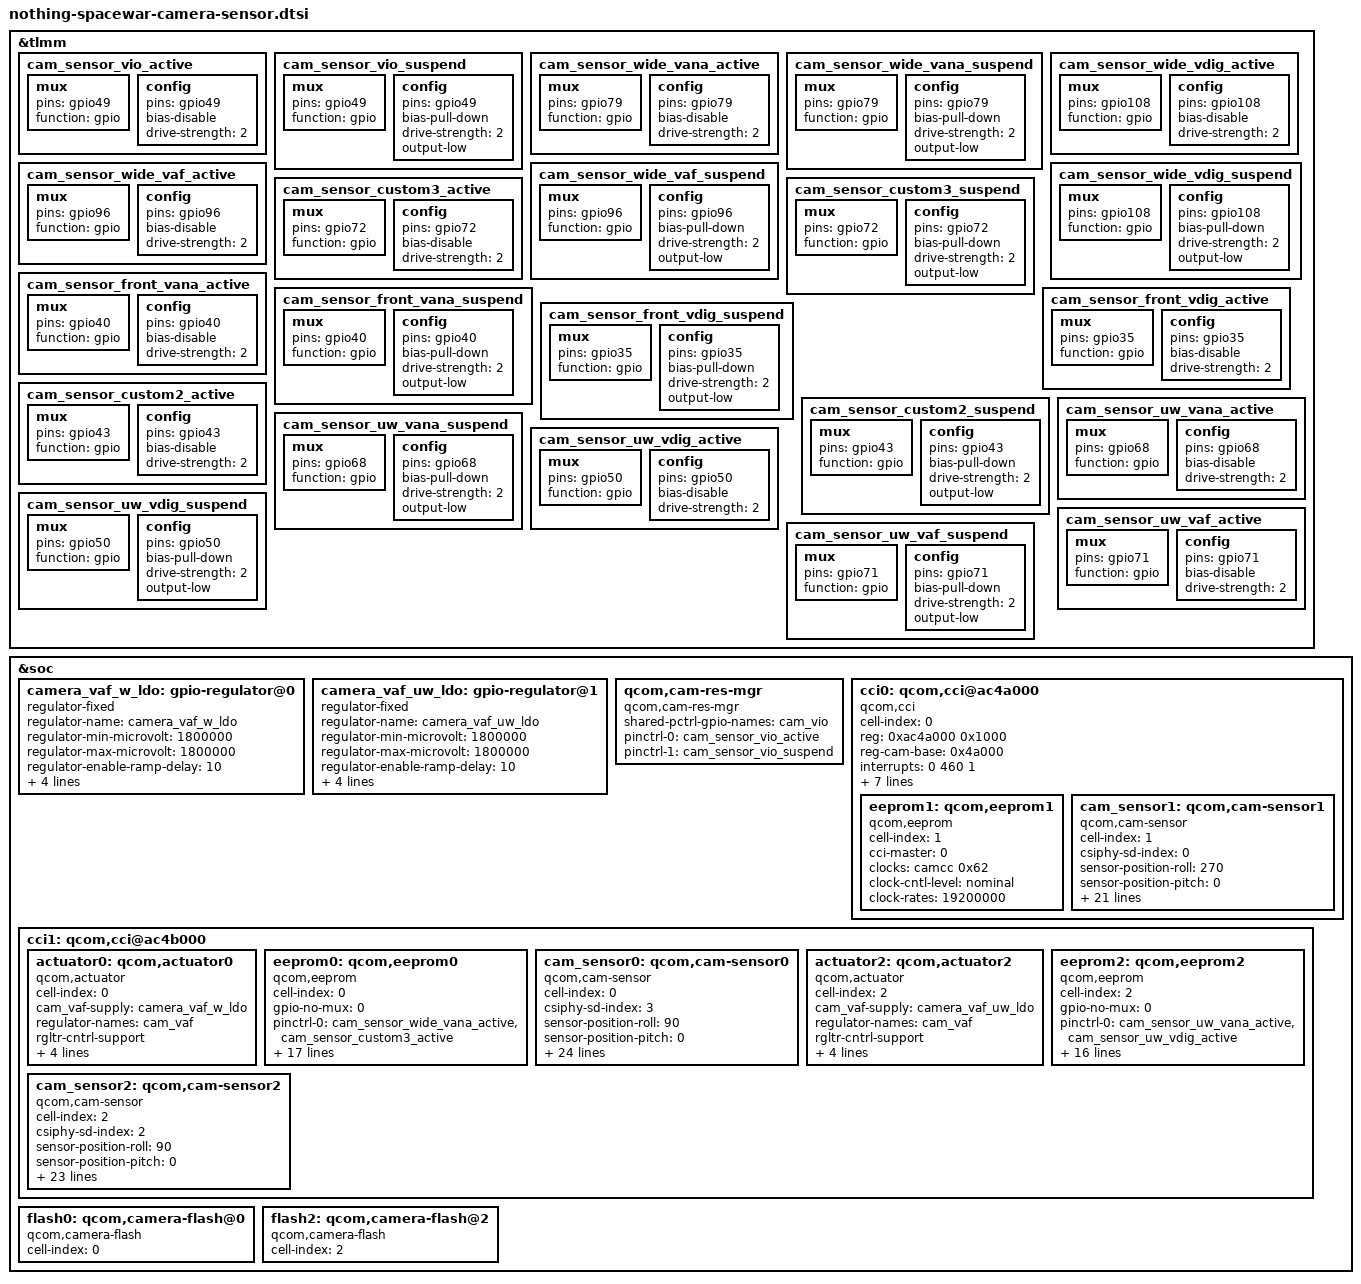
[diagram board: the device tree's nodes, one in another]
// Camera devicetree for Nothing Phone (1) "spacewar"

&tlmm {
	cam_sensor_vio_active: cam_sensor_vio_active {
		mux { pins = "gpio49"; function = "gpio"; };
		config { pins = "gpio49"; bias-disable; drive-strength = <2>; };
	};
	cam_sensor_vio_suspend: cam_sensor_vio_suspend {
		mux { pins = "gpio49"; function = "gpio"; };
		config { pins = "gpio49"; bias-pull-down; drive-strength = <2>; output-low; };
	};

	/* Wide (cam-sensor0) */
	cam_sensor_wide_vana_active: cam_sensor_wide_vana_active {
		mux { pins = "gpio79"; function = "gpio"; };
		config { pins = "gpio79"; bias-disable; drive-strength = <2>; };
	};
	cam_sensor_wide_vana_suspend: cam_sensor_wide_vana_suspend {
		mux { pins = "gpio79"; function = "gpio"; };
		config { pins = "gpio79"; bias-pull-down; drive-strength = <2>; output-low; };
	};
	cam_sensor_wide_vdig_active: cam_sensor_wide_vdig_active {
		mux { pins = "gpio108"; function = "gpio"; };
		config { pins = "gpio108"; bias-disable; drive-strength = <2>; };
	};
	cam_sensor_wide_vdig_suspend: cam_sensor_wide_vdig_suspend {
		mux { pins = "gpio108"; function = "gpio"; };
		config { pins = "gpio108"; bias-pull-down; drive-strength = <2>; output-low; };
	};
	cam_sensor_wide_vaf_active: cam_sensor_wide_vaf_active {
		mux { pins = "gpio96"; function = "gpio"; };
		config { pins = "gpio96"; bias-disable; drive-strength = <2>; };
	};
	cam_sensor_wide_vaf_suspend: cam_sensor_wide_vaf_suspend {
		mux { pins = "gpio96"; function = "gpio"; };
		config { pins = "gpio96"; bias-pull-down; drive-strength = <2>; output-low; };
	};
	cam_sensor_custom3_active: cam_sensor_custom3_active {
		mux { pins = "gpio72"; function = "gpio"; };
		config { pins = "gpio72"; bias-disable; drive-strength = <2>; };
	};
	cam_sensor_custom3_suspend: cam_sensor_custom3_suspend {
		mux { pins = "gpio72"; function = "gpio"; };
		config { pins = "gpio72"; bias-pull-down; drive-strength = <2>; output-low; };
	};

	/* Front (cam-sensor1) */
	cam_sensor_front_vana_active: cam_sensor_front_vana_active {
		mux { pins = "gpio40"; function = "gpio"; };
		config { pins = "gpio40"; bias-disable; drive-strength = <2>; };
	};
	cam_sensor_front_vana_suspend: cam_sensor_front_vana_suspend {
		mux { pins = "gpio40"; function = "gpio"; };
		config { pins = "gpio40"; bias-pull-down; drive-strength = <2>; output-low; };
	};
	cam_sensor_front_vdig_active: cam_sensor_front_vdig_active {
		mux { pins = "gpio35"; function = "gpio"; };
		config { pins = "gpio35"; bias-disable; drive-strength = <2>; };
	};
	cam_sensor_front_vdig_suspend: cam_sensor_front_vdig_suspend {
		mux { pins = "gpio35"; function = "gpio"; };
		config { pins = "gpio35"; bias-pull-down; drive-strength = <2>; output-low; };
	};
	cam_sensor_custom2_active: cam_sensor_custom2_active {
		mux { pins = "gpio43"; function = "gpio"; };
		config { pins = "gpio43"; bias-disable; drive-strength = <2>; };
	};
	cam_sensor_custom2_suspend: cam_sensor_custom2_suspend {
		mux { pins = "gpio43"; function = "gpio"; };
		config { pins = "gpio43"; bias-pull-down; drive-strength = <2>; output-low; };
	};

	/* Ultrawide (cam-sensor2) */
	cam_sensor_uw_vana_active: cam_sensor_uw_vana_active {
		mux { pins = "gpio68"; function = "gpio"; };
		config { pins = "gpio68"; bias-disable; drive-strength = <2>; };
	};
	cam_sensor_uw_vana_suspend: cam_sensor_uw_vana_suspend {
		mux { pins = "gpio68"; function = "gpio"; };
		config { pins = "gpio68"; bias-pull-down; drive-strength = <2>; output-low; };
	};
	cam_sensor_uw_vdig_active: cam_sensor_uw_vdig_active {
		mux { pins = "gpio50"; function = "gpio"; };
		config { pins = "gpio50"; bias-disable; drive-strength = <2>; };
	};
	cam_sensor_uw_vdig_suspend: cam_sensor_uw_vdig_suspend {
		mux { pins = "gpio50"; function = "gpio"; };
		config { pins = "gpio50"; bias-pull-down; drive-strength = <2>; output-low; };
	};
	cam_sensor_uw_vaf_active: cam_sensor_uw_vaf_active {
		mux { pins = "gpio71"; function = "gpio"; };
		config { pins = "gpio71"; bias-disable; drive-strength = <2>; };
	};
	cam_sensor_uw_vaf_suspend: cam_sensor_uw_vaf_suspend {
		mux { pins = "gpio71"; function = "gpio"; };
		config { pins = "gpio71"; bias-pull-down; drive-strength = <2>; output-low; };
	};
};

&soc {
	/* AF VCM LDOs - fixed 1.8V, gpio-enabled */
	camera_vaf_w_ldo: gpio-regulator@0 {
		compatible = "regulator-fixed";
		regulator-name = "camera_vaf_w_ldo";
		regulator-min-microvolt = <1800000>;
		regulator-max-microvolt = <1800000>;
		regulator-enable-ramp-delay = <10>;
		enable-active-high;
		pinctrl-names = "cam_af0_active", "cam_af0_suspend";
		pinctrl-0 = <&cam_sensor_wide_vaf_active>;
		pinctrl-1 = <&cam_sensor_wide_vaf_suspend>;
		gpio = <&tlmm 96 0>;
	};

	camera_vaf_uw_ldo: gpio-regulator@1 {
		compatible = "regulator-fixed";
		regulator-name = "camera_vaf_uw_ldo";
		regulator-min-microvolt = <1800000>;
		regulator-max-microvolt = <1800000>;
		regulator-enable-ramp-delay = <10>;
		enable-active-high;
		pinctrl-names = "cam_af1_active", "cam_af1_suspend";
		pinctrl-0 = <&cam_sensor_uw_vaf_active>;
		pinctrl-1 = <&cam_sensor_uw_vaf_suspend>;
		gpio = <&tlmm 71 0>;
	};

	qcom,cam-res-mgr {
		compatible = "qcom,cam-res-mgr";
		shared-pctrl-gpio-names = "cam_vio";
		pinctrl-names = "cam_vio_active", "cam_vio_suspend";
		pinctrl-0 = <&cam_sensor_vio_active>;
		pinctrl-1 = <&cam_sensor_vio_suspend>;
		status = "ok";
	};

	cci0: qcom,cci@ac4a000 {
		cell-index = <0>;
		compatible = "qcom,cci", "simple-bus";
		reg = <0xac4a000 0x1000>;
		reg-names = "cci";
		reg-cam-base = <0x4a000>;
		interrupt-names = "cci";
		interrupts = <0 460 1>;
		status = "ok";
		gpios = <&tlmm 69 0>, <&tlmm 70 0>;
		gpio-req-tbl-num = <0 1>;
		gpio-req-tbl-flags = <1 1>;
		gpio-req-tbl-label = "CCI_I2C_DATA0", "CCI_I2C_CLK0";
		clock-cntl-level = "lowsvs";
		clock-rates = <37500000 0>;
		#address-cells = <1>;
		#size-cells = <0>;

		/* ===== Front sensor (cci-master 0) ===== */
		eeprom1: qcom,eeprom1 {
			cell-index = <1>;
			compatible = "qcom,eeprom";
			cci-master = <0>;
			status = "ok";
			clocks = <&camcc 0x62>;
			clock-names = "cam_clk";
			clock-cntl-level = "nominal";
			clock-rates = <19200000>;
		};

		cam_sensor1: qcom,cam-sensor1 {
			cell-index = <1>;
			compatible = "qcom,cam-sensor";
			csiphy-sd-index = <0>;
			sensor-position-roll = <270>;
			sensor-position-pitch = <0>;
			sensor-position-yaw = <0>;
			eeprom-src = <&eeprom1>;
			gpio-no-mux = <0>;
			pinctrl-names = "cam_default", "cam_suspend";
			pinctrl-0 = <&cam_sensor_front_vdig_active &cam_sensor_custom2_active>;
			pinctrl-1 = <&cam_sensor_front_vdig_suspend &cam_sensor_custom2_suspend>;
			gpios = <&tlmm 64 0>, <&tlmm 20 0>, <&tlmm 35 0>,
				<&tlmm 49 0>, <&tlmm 43 0>;
			gpio-reset = <1>;
			gpio-vdig = <2>;
			gpio-vio = <3>;
			gpio-custom2 = <4>;
			gpio-req-tbl-num = <0 1 2 3 4>;
			gpio-req-tbl-flags = <1 0 0 0 0>;
			gpio-req-tbl-label = "CAMIF_MCLK1", "CAM_RESET1", "CAM_VDIG1", "CAM_VIO1", "CAM_CUSTOM1";
			cci-master = <0>;
			status = "ok";
			clocks = <&camcc 0x5c>;
			clock-names = "cam_clk";
			clock-cntl-level = "nominal";
			clock-rates = <19200000>;
		};
	};

	cci1: qcom,cci@ac4b000 {
		/* Wide + ultrawide, cci-master 1/0 on the second CCI logical bus */
		#address-cells = <1>;
		#size-cells = <0>;

		/* ===== Wide sensor (cci-master 1) ===== */
		actuator0: qcom,actuator0 {
			cell-index = <0>;
			compatible = "qcom,actuator";
			cam_vaf-supply = <&camera_vaf_w_ldo>;
			regulator-names = "cam_vaf";
			rgltr-cntrl-support;
			rgltr-min-voltage = <1800000>;
			rgltr-max-voltage = <1800000>;
			rgltr-load-current = <1800000>;
			cci-master = <1>;
		};

		eeprom0: qcom,eeprom0 {
			cell-index = <0>;
			compatible = "qcom,eeprom";
			gpio-no-mux = <0>;
			pinctrl-names = "cam_default", "cam_suspend";
			pinctrl-0 = <&cam_sensor_wide_vana_active &cam_sensor_custom3_active>;
			pinctrl-1 = <&cam_sensor_wide_vana_suspend &cam_sensor_custom3_suspend>;
			gpios = <&tlmm 67 0>, <&tlmm 78 0>, <&tlmm 79 0>,
				<&tlmm 72 0>, <&tlmm 108 0>, <&tlmm 49 0>;
			gpio-reset = <1>;
			gpio-vana = <2>;
			gpio-custom1 = <3>;
			gpio-vdig = <4>;
			gpio-vio = <5>;
			gpio-req-tbl-num = <0 1 2 3 4 5>;
			gpio-req-tbl-flags = <1 0 0 0 0 0>;
			gpio-req-tbl-label = "CAMIF_MCLK0", "CAM_RESET0", "CAM_VANA0", "CAM_CUSTOM0", "CAM_VDIG0", "CAM_VIO0";
			cci-master = <1>;
			status = "ok";
			clocks = <&camcc 0x62>;
			clock-names = "cam_clk";
			clock-cntl-level = "nominal";
			clock-rates = <19200000>;
		};

		cam_sensor0: qcom,cam-sensor0 {
			cell-index = <0>;
			compatible = "qcom,cam-sensor";
			csiphy-sd-index = <3>;
			sensor-position-roll = <90>;
			sensor-position-pitch = <0>;
			sensor-position-yaw = <180>;
			actuator-src = <&actuator0>;
			eeprom-src = <&eeprom0>;
			led-flash-src = <&flash0>;
			gpio-no-mux = <0>;
			pinctrl-names = "cam_default", "cam_suspend";
			pinctrl-0 = <&cam_sensor_wide_vana_active &cam_sensor_custom3_active>;
			pinctrl-1 = <&cam_sensor_wide_vana_suspend &cam_sensor_custom3_suspend>;
			gpios = <&tlmm 67 0>, <&tlmm 78 0>, <&tlmm 79 0>,
				<&tlmm 108 0>, <&tlmm 49 0>, <&tlmm 72 0>;
			gpio-reset = <1>;
			gpio-vana = <2>;
			gpio-vdig = <3>;
			gpio-vio = <4>;
			gpio-custom1 = <5>;
			gpio-req-tbl-num = <0 1 2 3 4 5>;
			gpio-req-tbl-flags = <1 0 0 0 0 0>;
			gpio-req-tbl-label = "CAMIF_MCLK0", "CAM_RESET0", "CAM_VANA0", "CAM_VDIG0", "CAM_VIO0", "CAM_CUSTOM0";
			cci-master = <1>;
			status = "ok";
			clocks = <&camcc 0x62>;
			clock-names = "cam_clk";
			clock-cntl-level = "nominal";
			clock-rates = <19200000>;
		};

		/* ===== Ultrawide sensor (cci-master 0) ===== */
		actuator2: qcom,actuator2 {
			cell-index = <2>;
			compatible = "qcom,actuator";
			cam_vaf-supply = <&camera_vaf_uw_ldo>;
			regulator-names = "cam_vaf";
			rgltr-cntrl-support;
			rgltr-min-voltage = <1800000>;
			rgltr-max-voltage = <1800000>;
			rgltr-load-current = <1800000>;
			cci-master = <0>;
		};

		eeprom2: qcom,eeprom2 {
			cell-index = <2>;
			compatible = "qcom,eeprom";
			gpio-no-mux = <0>;
			pinctrl-names = "cam_default", "cam_suspend";
			pinctrl-0 = <&cam_sensor_uw_vana_active &cam_sensor_uw_vdig_active>;
			pinctrl-1 = <&cam_sensor_uw_vana_suspend &cam_sensor_uw_vdig_suspend>;
			gpios = <&tlmm 66 0>, <&tlmm 77 0>, <&tlmm 68 0>,
				<&tlmm 50 0>, <&tlmm 49 0>;
			gpio-reset = <1>;
			gpio-vana = <2>;
			gpio-vdig = <3>;
			gpio-vio = <4>;
			gpio-req-tbl-num = <0 1 2 3 4>;
			gpio-req-tbl-flags = <1 0 0 0 0>;
			gpio-req-tbl-label = "CAMIF_MCLK2", "CAM_RESET2", "CAM_VANA2", "CAM_VDIG2", "CAM_VIO2";
			cci-master = <0>;
			status = "ok";
			clocks = <&camcc 0x60>;
			clock-names = "cam_clk";
			clock-cntl-level = "nominal";
			clock-rates = <19200000>;
		};

		cam_sensor2: qcom,cam-sensor2 {
			cell-index = <2>;
			compatible = "qcom,cam-sensor";
			csiphy-sd-index = <2>;
			sensor-position-roll = <90>;
			sensor-position-pitch = <0>;
			sensor-position-yaw = <180>;
			eeprom-src = <&eeprom2>;
			actuator-src = <&actuator2>;
			led-flash-src = <&flash2>;
			gpio-no-mux = <0>;
			pinctrl-names = "cam_default", "cam_suspend";
			pinctrl-0 = <&cam_sensor_uw_vana_active &cam_sensor_uw_vdig_active>;
			pinctrl-1 = <&cam_sensor_uw_vana_suspend &cam_sensor_uw_vdig_suspend>;
			gpios = <&tlmm 66 0>, <&tlmm 77 0>, <&tlmm 68 0>,
				<&tlmm 50 0>, <&tlmm 49 0>;
			gpio-reset = <1>;
			gpio-vana = <2>;
			gpio-vdig = <3>;
			gpio-vio = <4>;
			gpio-req-tbl-num = <0 1 2 3 4>;
			gpio-req-tbl-flags = <1 0 0 0 0>;
			gpio-req-tbl-label = "CAMIF_MCLK2", "CAM_RESET2", "CAM_VANA2", "CAM_VDIG2", "CAM_VIO2";
			cci-master = <0>;
			status = "ok";
			clocks = <&camcc 0x60>;
			clock-names = "cam_clk";
			clock-cntl-level = "nominal";
			clock-rates = <19200000>;
		};
	};

	flash0: qcom,camera-flash@0 {
		cell-index = <0>;
		compatible = "qcom,camera-flash";
		status = "ok";
	};

	flash2: qcom,camera-flash@2 {
		cell-index = <2>;
		compatible = "qcom,camera-flash";
		status = "ok";
	};
};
